# HC32F472 register map
File version: 1.0
CPU: CM4 r0p1, little endian, MPU, FPU, 4 interrupt priority bits
Registers are 32-bit, read-write, reset 0x0 unless marked. A register's access mark holds for its fields unless they carry their own. Offsets are from the block's base; [hi:lo] are bit positions; {n}, {i} and the like mark numbered series; 'fields as' and 'values as' point back to an identical list.

## EMB_CTL1
Base 0x00000000
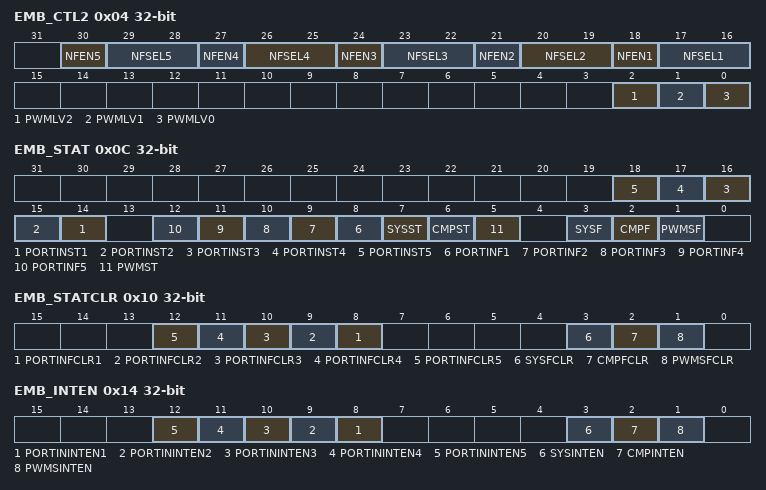
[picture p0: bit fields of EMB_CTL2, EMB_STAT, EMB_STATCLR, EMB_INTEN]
0x04 EMB_CTL2
  [3n+15] NFEN{n} (n=1..5), [3n+14:3n+13] NFSEL{n} (n=1..5), [2] PWMLV2, [1] PWMLV1, [0] PWMLV0
0x08 EMB_SOE
  [0] SOE
0x0C EMB_STAT ro
  [n+13] PORTINST{n} (n=1..5), [n+7] PORTINF{n} (n=1..5), [7] SYSST, [6] CMPST, [5] PWMST, [3] SYSF, [2] CMPF, [1] PWMSF
0x10 EMB_STATCLR wo
  [n+7] PORTINFCLR{n} (n=1..5), [3] SYSFCLR, [2] CMPFCLR, [1] PWMSFCLR
0x14 EMB_INTEN
  [n+7] PORTININTEN{n} (n=1..5), [3] SYSINTEN, [2] CMPINTEN, [1] PWMSINTEN
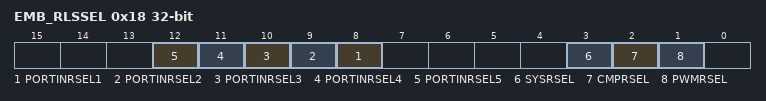
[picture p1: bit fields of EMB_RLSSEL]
0x18 EMB_RLSSEL
  [n+7] PORTINRSEL{n} (n=1..5), [3] SYSRSEL, [2] CMPRSEL, [1] PWMRSEL

## FCM
Base 0x40048400
0x00 LVR
  [15:0] LVR
0x04 UVR
  [15:0] UVR
0x08 CNTR ro
  [15:0] CNTR
0x0C STR
  [0] START
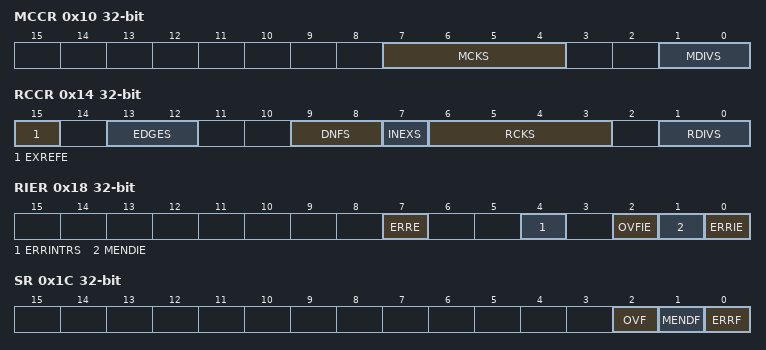
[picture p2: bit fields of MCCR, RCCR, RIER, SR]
0x10 MCCR
  [7:4] MCKS, [1:0] MDIVS
0x14 RCCR
  [15] EXREFE, [13:12] EDGES, [9:8] DNFS, [7] INEXS, [6:3] RCKS, [1:0] RDIVS
0x18 RIER
  [7] ERRE, [4] ERRINTRS, [2] OVFIE, [1] MENDIE, [0] ERRIE
0x1C SR ro
  [2] OVF, [1] MENDF, [0] ERRF
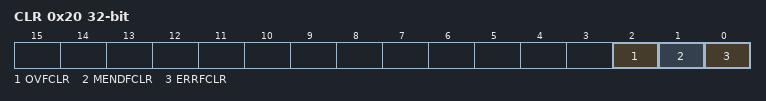
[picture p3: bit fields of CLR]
0x20 CLR wo
  [2] OVFCLR, [1] MENDFCLR, [0] ERRFCLR

## FMAC1 — desc FMAC
Base 0x40058000
Same registers: FMAC2 0x40058400, FMAC3 0x40058800, FMAC4 0x40058C00
0x00 ENR
  [0] FMACEN
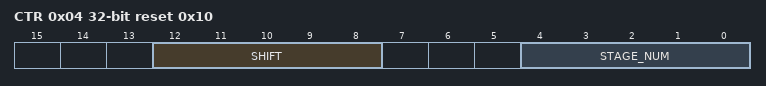
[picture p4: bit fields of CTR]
0x04 CTR reset 0x10
  [12:8] SHIFT, [4:0] STAGE_NUM
0x08 IER
  [0] INTEN
0x0C DTR
  [15:0] DIN
0x10 RTR0
0x14 RTR1
0x18 STR
  [31] READY
{0x20+4i} COR{i} (i=0..16)
  [15:0] CIN

## GPIO
Base 0x40053800
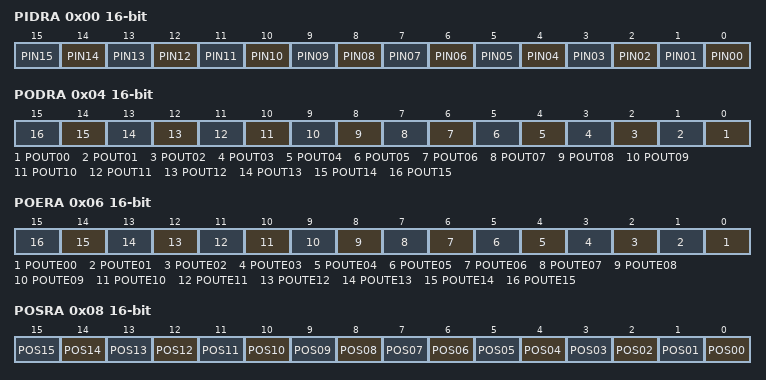
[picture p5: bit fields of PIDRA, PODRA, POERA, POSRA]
0x00 PIDRA 16-bit ro
  [n] PIN{n:02} (n=0..15)
0x04 PODRA 16-bit
  [n] POUT{n:02} (n=0..15)
0x06 POERA 16-bit
  [n] POUTE{n:02} (n=0..15)
0x08 POSRA 16-bit wo
  [n] POS{n:02} (n=0..15)
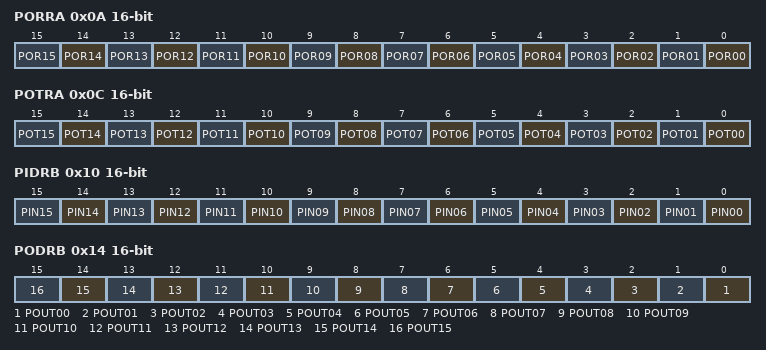
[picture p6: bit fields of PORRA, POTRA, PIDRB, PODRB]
0x0A PORRA 16-bit wo
  [n] POR{n:02} (n=0..15)
0x0C POTRA 16-bit wo
  [n] POT{n:02} (n=0..15)
0x10 PIDRB 16-bit ro
  [n] PIN{n:02} (n=0..15)
0x14 PODRB 16-bit
  [n] POUT{n:02} (n=0..15)
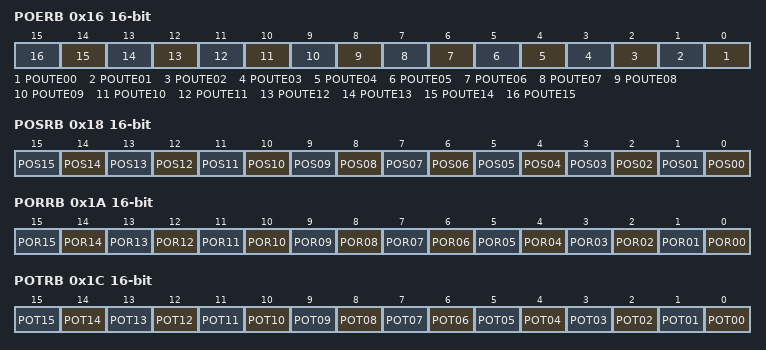
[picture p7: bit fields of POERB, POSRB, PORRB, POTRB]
0x16 POERB 16-bit
  [n] POUTE{n:02} (n=0..15)
0x18 POSRB 16-bit wo
  [n] POS{n:02} (n=0..15)
0x1A PORRB 16-bit wo
  [n] POR{n:02} (n=0..15)
0x1C POTRB 16-bit wo
  [n] POT{n:02} (n=0..15)
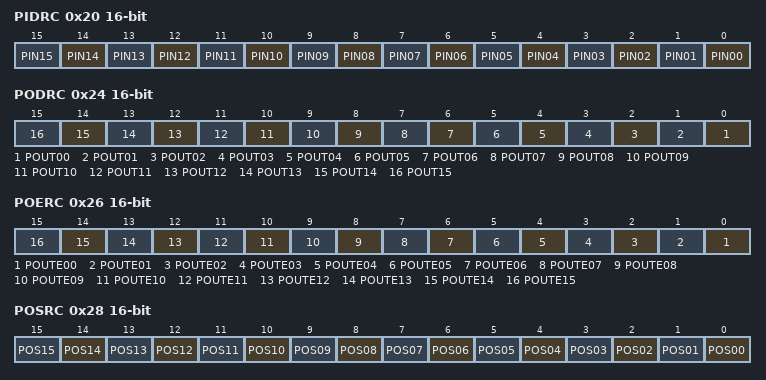
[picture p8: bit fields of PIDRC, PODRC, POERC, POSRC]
0x20 PIDRC 16-bit ro
  [n] PIN{n:02} (n=0..15)
0x24 PODRC 16-bit
  [n] POUT{n:02} (n=0..15)
0x26 POERC 16-bit
  [n] POUTE{n:02} (n=0..15)
0x28 POSRC 16-bit wo
  [n] POS{n:02} (n=0..15)
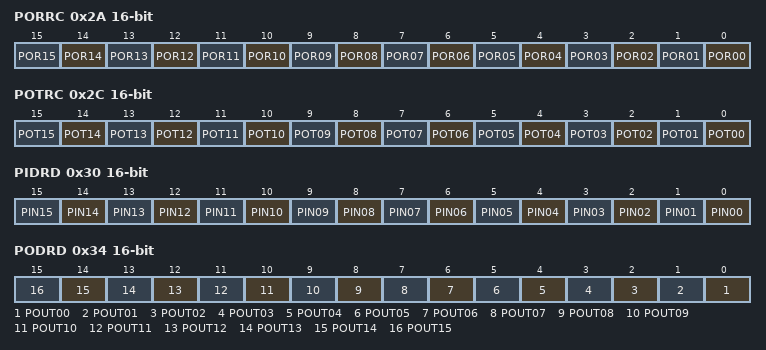
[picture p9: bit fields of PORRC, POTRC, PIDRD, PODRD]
0x2A PORRC 16-bit wo
  [n] POR{n:02} (n=0..15)
0x2C POTRC 16-bit wo
  [n] POT{n:02} (n=0..15)
0x30 PIDRD 16-bit ro
  [n] PIN{n:02} (n=0..15)
0x34 PODRD 16-bit
  [n] POUT{n:02} (n=0..15)
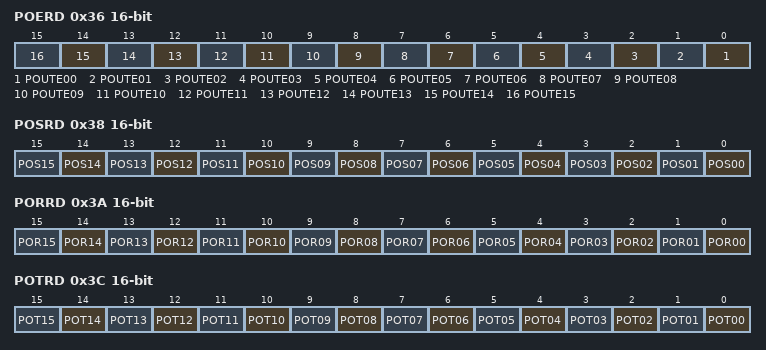
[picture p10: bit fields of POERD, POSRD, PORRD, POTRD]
0x36 POERD 16-bit
  [n] POUTE{n:02} (n=0..15)
0x38 POSRD 16-bit wo
  [n] POS{n:02} (n=0..15)
0x3A PORRD 16-bit wo
  [n] POR{n:02} (n=0..15)
0x3C POTRD 16-bit wo
  [n] POT{n:02} (n=0..15)
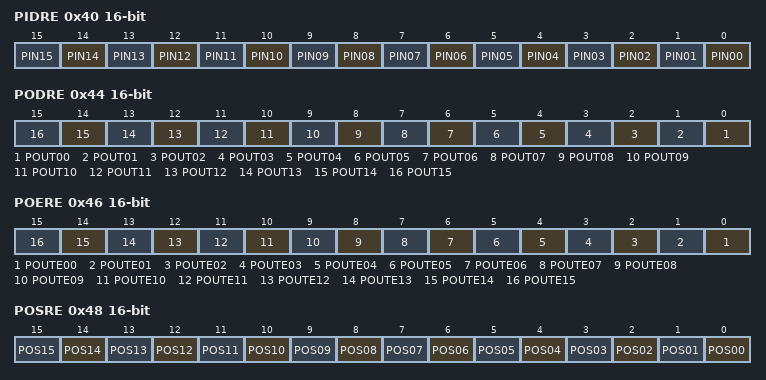
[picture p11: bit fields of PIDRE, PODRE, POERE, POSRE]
0x40 PIDRE 16-bit ro
  [n] PIN{n:02} (n=0..15)
0x44 PODRE 16-bit
  [n] POUT{n:02} (n=0..15)
0x46 POERE 16-bit
  [n] POUTE{n:02} (n=0..15)
0x48 POSRE 16-bit wo
  [n] POS{n:02} (n=0..15)
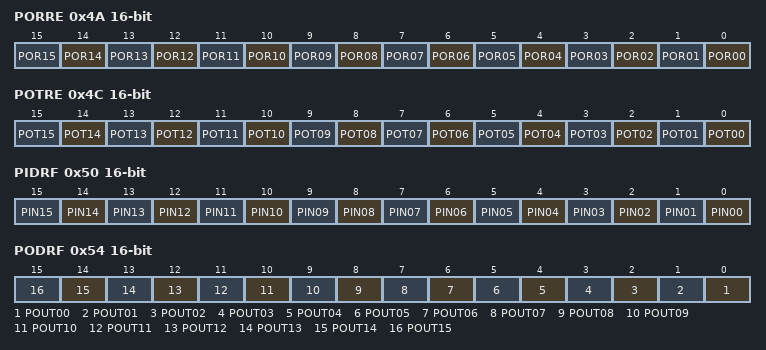
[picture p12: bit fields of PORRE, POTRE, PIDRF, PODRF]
0x4A PORRE 16-bit wo
  [n] POR{n:02} (n=0..15)
0x4C POTRE 16-bit wo
  [n] POT{n:02} (n=0..15)
0x50 PIDRF 16-bit ro
  [n] PIN{n:02} (n=0..15)
0x54 PODRF 16-bit
  [n] POUT{n:02} (n=0..15)
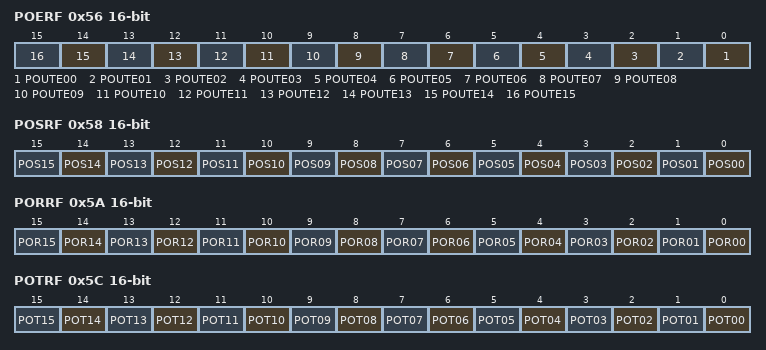
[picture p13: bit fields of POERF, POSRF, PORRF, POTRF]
0x56 POERF 16-bit
  [n] POUTE{n:02} (n=0..15)
0x58 POSRF 16-bit wo
  [n] POS{n:02} (n=0..15)
0x5A PORRF 16-bit wo
  [n] POR{n:02} (n=0..15)
0x5C POTRF 16-bit wo
  [n] POT{n:02} (n=0..15)
0x3F4 PSPCR 16-bit reset 0x1F
  [4:0] SPFE
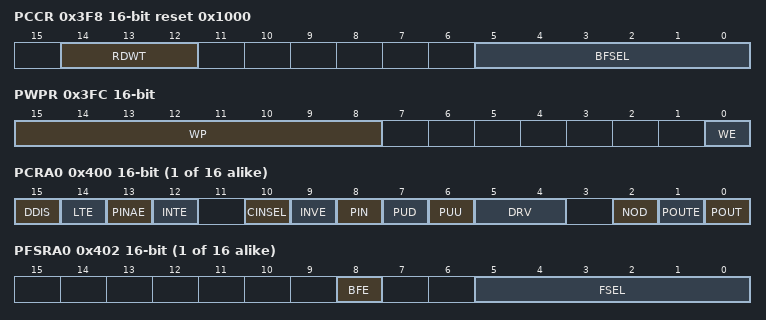
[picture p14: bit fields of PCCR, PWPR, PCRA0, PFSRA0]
0x3F8 PCCR 16-bit reset 0x1000
  [14:12] RDWT, [5:0] BFSEL
0x3FC PWPR 16-bit
  [15:8] WP wo, [0] WE
{0x400+4i} PCRA{i} 16-bit (i=0..15)
  [15] DDIS, [14] LTE, [13] PINAE, [12] INTE, [10] CINSEL, [9] INVE, [8] PIN ro, [7] PUD, [6] PUU, [5:4] DRV, [2] NOD, [1] POUTE, [0] POUT
{0x402+4i} PFSRA{i} 16-bit (i=0..15)
  [8] BFE, [5:0] FSEL
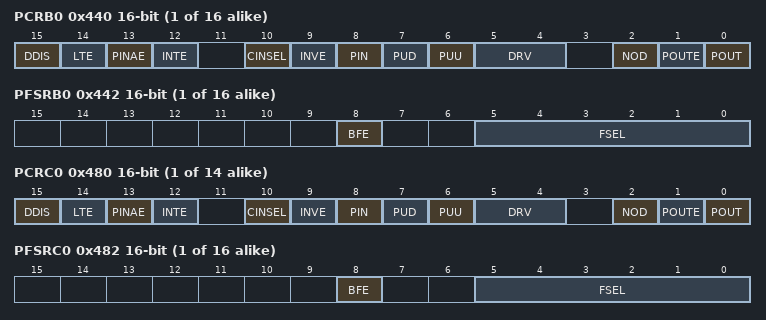
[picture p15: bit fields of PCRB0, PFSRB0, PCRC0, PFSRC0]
{0x440+4i} PCRB{i} 16-bit (i=0..15)
  fields as PCRA0
{0x442+4i} PFSRB{i} 16-bit (i=0..15)
  [8] BFE, [5:0] FSEL
{0x480+4i} PCRC{i} 16-bit (i=0..13)
  fields as PCRA0
{0x482+4i} PFSRC{i} 16-bit (i=0..15)
  [8] BFE, [5:0] FSEL
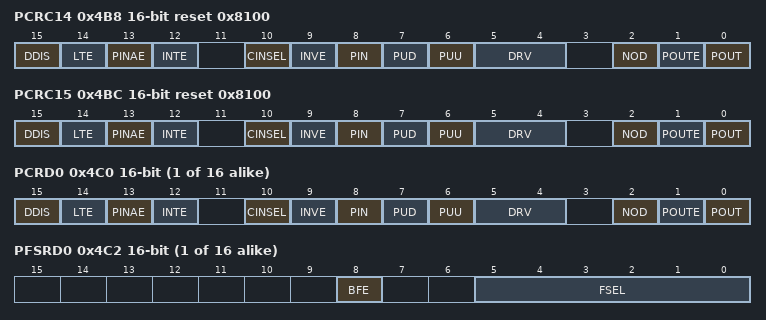
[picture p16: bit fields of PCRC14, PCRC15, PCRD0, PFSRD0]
0x4B8 PCRC14 16-bit reset 0x8100
  fields as PCRA0
0x4BC PCRC15 16-bit reset 0x8100
  fields as PCRA0
{0x4C0+4i} PCRD{i} 16-bit (i=0..15)
  fields as PCRA0
{0x4C2+4i} PFSRD{i} 16-bit (i=0..15)
  [8] BFE, [5:0] FSEL
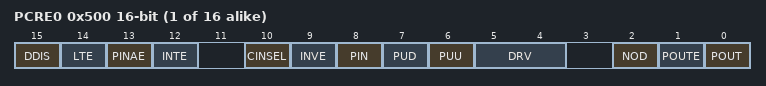
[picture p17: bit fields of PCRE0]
{0x500+4i} PCRE{i} 16-bit (i=0..15)
  fields as PCRA0
{0x502+4i} PFSRE{i} 16-bit (i=0..15)
  [8] BFE, [5:0] FSEL
{0x540+4i} PCRF{i} 16-bit (i=0..8)
  fields as PCRA0
{0x542+4i} PFSRF{i} 16-bit (i=0..8)
  [8] BFE, [5:0] FSEL
